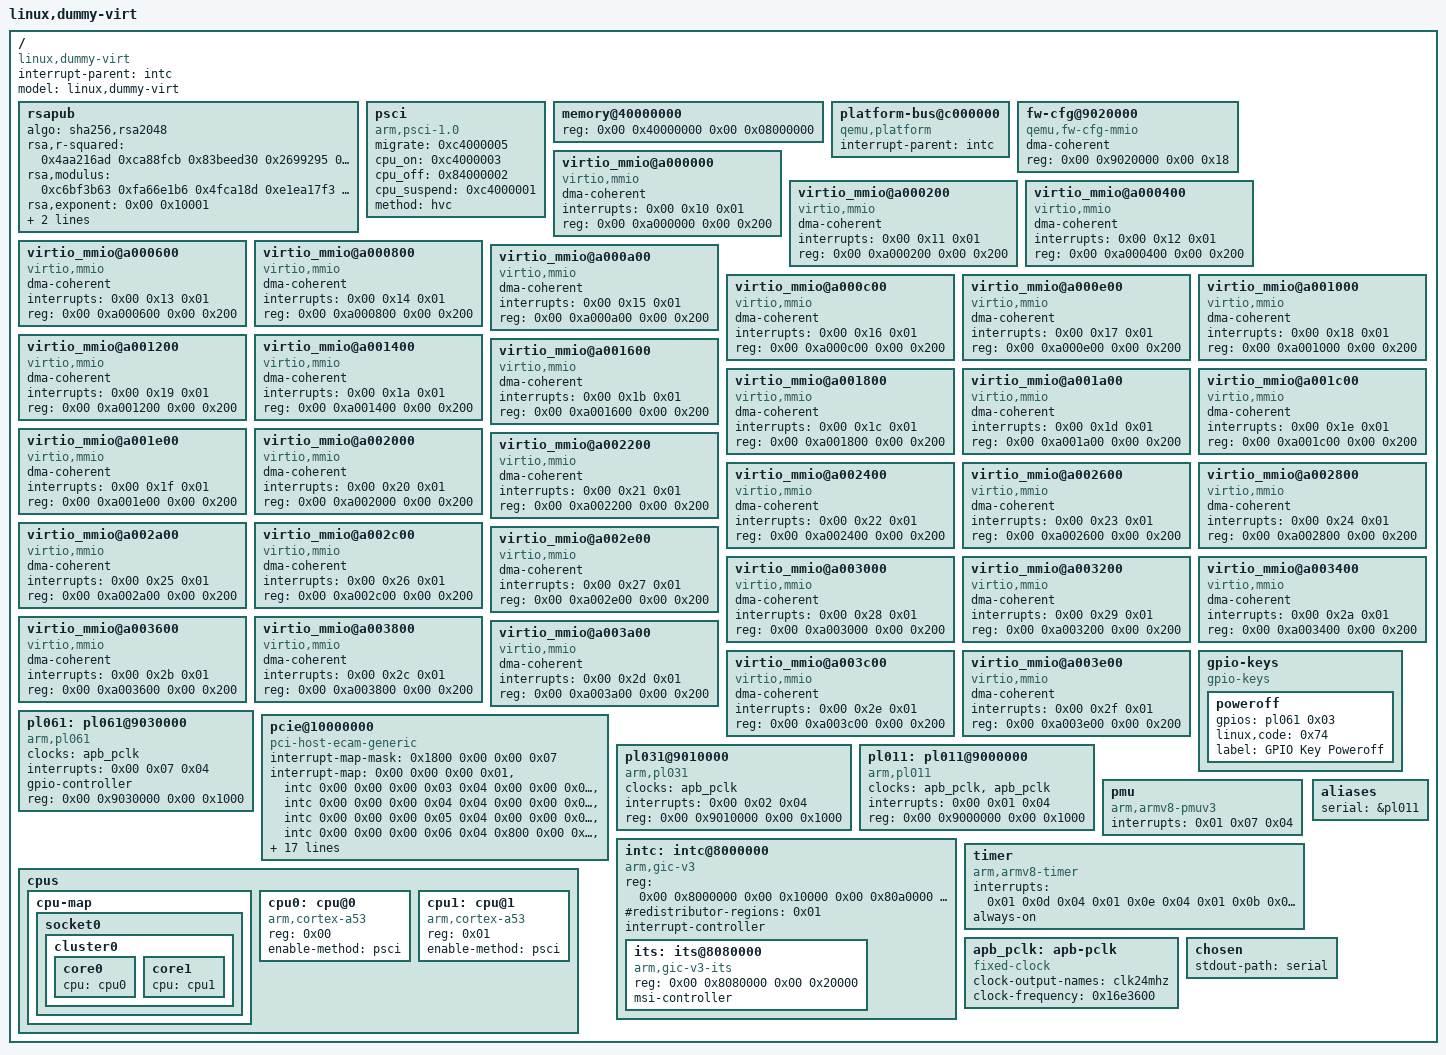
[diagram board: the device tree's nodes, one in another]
/dts-v1/;

/ {
	interrupt-parent = <&intc>;
	model = "linux,dummy-virt";
	#size-cells = <0x02>;
	#address-cells = <0x02>;
	compatible = "linux,dummy-virt";

	rsapub {
		algo = "sha256,rsa2048";
		rsa,r-squared = <0x4aa216ad 0xca88fcb 0x83beed30 0x2699295 0xf1afaef1 0x663e275e 0x19fa1227 0xb83d5ba3 0x43e199b8 0xd6899b14 0x4080062c 0xe27ea068 0xb2cbdb31 0x39768148 0x6f4cea3e 0x546d6990 0x51e88129 0xdb19710 0xa0184961 0x5ab6231d 0xc429c3dc 0xe7d1cb2b 0x63da5958 0x840e2b14 0x6644892a 0xb4f9f666 0x2552653a 0x16837f33 0x7ed7004a 0xba52a9f3 0x25413042 0xb91ebefd 0x2e3ef636 0x78a22c37 0x52dc3454 0x63b33b5 0xacee4539 0x49e8f7b6 0x8022eb2e 0xa7a001ea 0x9b777c26 0x40e1b15c 0x6eeed8e8 0xad6357a0 0x7f3c8cda 0x26c5c372 0xe377980c 0x3e431736 0xcdea5f7d 0x110a697d 0x111d53b0 0x27730100 0x738f9021 0x1fd3392a 0xaff45290 0x63d99fe7 0x4a09e67a 0xdbefd05d 0xab39db9a 0xe329a097 0x8de7c060 0x11e8d8ea 0x37a7bced 0xe69151c6>;
		rsa,modulus = <0xc6bf3b63 0xfa66e1b6 0x4fca18d 0xe1ea17f3 0xae2a3788 0x447abb5a 0x84d89a56 0xa434a3ac 0x7704144d 0xb8bd8b6e 0x27553191 0x89627597 0xbd01c377 0x52e8e12c 0x68712319 0x9aa26344 0xa7e7bca8 0xd727d465 0xe27ec55e 0x5ce4371 0x2d53f51d 0x3a14ba49 0x6ecacc06 0xd6561ff7 0xe3d4cb69 0x1238e84c 0x3b7a91b4 0xa4dfc5b4 0x273e10df 0x132defd2 0xf65991a9 0xd9da33a1 0x2e41eb73 0xe48ef4b5 0x619e852 0xc041f985 0x7777707e 0xe8074f31 0x20276d03 0xce9bbc47 0x321b9398 0x2a8e88f1 0xff1bad1c 0x8f127e80 0xa64ff0e8 0xabfa8a48 0x440102f1 0x85509ce7 0xd56d3b1f 0x8f580f09 0xfce683f1 0xcc9c589a 0x4b31ca83 0xafb93fbc 0xf1669786 0xe7cd623 0x6797b351 0xc598703f 0x1ed05880 0xd96da721 0x5d976f69 0xa6ccb449 0x5e6be39 0xb6ffdc83>;
		rsa,exponent = <0x00 0x10001>;
		rsa,n0-inverse = <0xcd33add5>;
		rsa,num-bits = <0x800>;
	};

	psci {
		migrate = <0xc4000005>;
		cpu_on = <0xc4000003>;
		cpu_off = <0x84000002>;
		cpu_suspend = <0xc4000001>;
		method = "hvc";
		compatible = "arm,psci-1.0", "arm,psci-0.2", "arm,psci";
	};

	memory@40000000 {
		reg = <0x00 0x40000000 0x00 0x08000000>;
		device_type = "memory";
	};

	platform-bus@c000000 {
		interrupt-parent = <&intc>;
		ranges = <0x00 0x00 0xc000000 0x2000000>;
		#address-cells = <0x01>;
		#size-cells = <0x01>;
		compatible = "qemu,platform", "simple-bus";
	};

	fw-cfg@9020000 {
		dma-coherent;
		reg = <0x00 0x9020000 0x00 0x18>;
		compatible = "qemu,fw-cfg-mmio";
	};

	virtio_mmio@a000000 {
		dma-coherent;
		interrupts = <0x00 0x10 0x01>;
		reg = <0x00 0xa000000 0x00 0x200>;
		compatible = "virtio,mmio";
	};

	virtio_mmio@a000200 {
		dma-coherent;
		interrupts = <0x00 0x11 0x01>;
		reg = <0x00 0xa000200 0x00 0x200>;
		compatible = "virtio,mmio";
	};

	virtio_mmio@a000400 {
		dma-coherent;
		interrupts = <0x00 0x12 0x01>;
		reg = <0x00 0xa000400 0x00 0x200>;
		compatible = "virtio,mmio";
	};

	virtio_mmio@a000600 {
		dma-coherent;
		interrupts = <0x00 0x13 0x01>;
		reg = <0x00 0xa000600 0x00 0x200>;
		compatible = "virtio,mmio";
	};

	virtio_mmio@a000800 {
		dma-coherent;
		interrupts = <0x00 0x14 0x01>;
		reg = <0x00 0xa000800 0x00 0x200>;
		compatible = "virtio,mmio";
	};

	virtio_mmio@a000a00 {
		dma-coherent;
		interrupts = <0x00 0x15 0x01>;
		reg = <0x00 0xa000a00 0x00 0x200>;
		compatible = "virtio,mmio";
	};

	virtio_mmio@a000c00 {
		dma-coherent;
		interrupts = <0x00 0x16 0x01>;
		reg = <0x00 0xa000c00 0x00 0x200>;
		compatible = "virtio,mmio";
	};

	virtio_mmio@a000e00 {
		dma-coherent;
		interrupts = <0x00 0x17 0x01>;
		reg = <0x00 0xa000e00 0x00 0x200>;
		compatible = "virtio,mmio";
	};

	virtio_mmio@a001000 {
		dma-coherent;
		interrupts = <0x00 0x18 0x01>;
		reg = <0x00 0xa001000 0x00 0x200>;
		compatible = "virtio,mmio";
	};

	virtio_mmio@a001200 {
		dma-coherent;
		interrupts = <0x00 0x19 0x01>;
		reg = <0x00 0xa001200 0x00 0x200>;
		compatible = "virtio,mmio";
	};

	virtio_mmio@a001400 {
		dma-coherent;
		interrupts = <0x00 0x1a 0x01>;
		reg = <0x00 0xa001400 0x00 0x200>;
		compatible = "virtio,mmio";
	};

	virtio_mmio@a001600 {
		dma-coherent;
		interrupts = <0x00 0x1b 0x01>;
		reg = <0x00 0xa001600 0x00 0x200>;
		compatible = "virtio,mmio";
	};

	virtio_mmio@a001800 {
		dma-coherent;
		interrupts = <0x00 0x1c 0x01>;
		reg = <0x00 0xa001800 0x00 0x200>;
		compatible = "virtio,mmio";
	};

	virtio_mmio@a001a00 {
		dma-coherent;
		interrupts = <0x00 0x1d 0x01>;
		reg = <0x00 0xa001a00 0x00 0x200>;
		compatible = "virtio,mmio";
	};

	virtio_mmio@a001c00 {
		dma-coherent;
		interrupts = <0x00 0x1e 0x01>;
		reg = <0x00 0xa001c00 0x00 0x200>;
		compatible = "virtio,mmio";
	};

	virtio_mmio@a001e00 {
		dma-coherent;
		interrupts = <0x00 0x1f 0x01>;
		reg = <0x00 0xa001e00 0x00 0x200>;
		compatible = "virtio,mmio";
	};

	virtio_mmio@a002000 {
		dma-coherent;
		interrupts = <0x00 0x20 0x01>;
		reg = <0x00 0xa002000 0x00 0x200>;
		compatible = "virtio,mmio";
	};

	virtio_mmio@a002200 {
		dma-coherent;
		interrupts = <0x00 0x21 0x01>;
		reg = <0x00 0xa002200 0x00 0x200>;
		compatible = "virtio,mmio";
	};

	virtio_mmio@a002400 {
		dma-coherent;
		interrupts = <0x00 0x22 0x01>;
		reg = <0x00 0xa002400 0x00 0x200>;
		compatible = "virtio,mmio";
	};

	virtio_mmio@a002600 {
		dma-coherent;
		interrupts = <0x00 0x23 0x01>;
		reg = <0x00 0xa002600 0x00 0x200>;
		compatible = "virtio,mmio";
	};

	virtio_mmio@a002800 {
		dma-coherent;
		interrupts = <0x00 0x24 0x01>;
		reg = <0x00 0xa002800 0x00 0x200>;
		compatible = "virtio,mmio";
	};

	virtio_mmio@a002a00 {
		dma-coherent;
		interrupts = <0x00 0x25 0x01>;
		reg = <0x00 0xa002a00 0x00 0x200>;
		compatible = "virtio,mmio";
	};

	virtio_mmio@a002c00 {
		dma-coherent;
		interrupts = <0x00 0x26 0x01>;
		reg = <0x00 0xa002c00 0x00 0x200>;
		compatible = "virtio,mmio";
	};

	virtio_mmio@a002e00 {
		dma-coherent;
		interrupts = <0x00 0x27 0x01>;
		reg = <0x00 0xa002e00 0x00 0x200>;
		compatible = "virtio,mmio";
	};

	virtio_mmio@a003000 {
		dma-coherent;
		interrupts = <0x00 0x28 0x01>;
		reg = <0x00 0xa003000 0x00 0x200>;
		compatible = "virtio,mmio";
	};

	virtio_mmio@a003200 {
		dma-coherent;
		interrupts = <0x00 0x29 0x01>;
		reg = <0x00 0xa003200 0x00 0x200>;
		compatible = "virtio,mmio";
	};

	virtio_mmio@a003400 {
		dma-coherent;
		interrupts = <0x00 0x2a 0x01>;
		reg = <0x00 0xa003400 0x00 0x200>;
		compatible = "virtio,mmio";
	};

	virtio_mmio@a003600 {
		dma-coherent;
		interrupts = <0x00 0x2b 0x01>;
		reg = <0x00 0xa003600 0x00 0x200>;
		compatible = "virtio,mmio";
	};

	virtio_mmio@a003800 {
		dma-coherent;
		interrupts = <0x00 0x2c 0x01>;
		reg = <0x00 0xa003800 0x00 0x200>;
		compatible = "virtio,mmio";
	};

	virtio_mmio@a003a00 {
		dma-coherent;
		interrupts = <0x00 0x2d 0x01>;
		reg = <0x00 0xa003a00 0x00 0x200>;
		compatible = "virtio,mmio";
	};

	virtio_mmio@a003c00 {
		dma-coherent;
		interrupts = <0x00 0x2e 0x01>;
		reg = <0x00 0xa003c00 0x00 0x200>;
		compatible = "virtio,mmio";
	};

	virtio_mmio@a003e00 {
		dma-coherent;
		interrupts = <0x00 0x2f 0x01>;
		reg = <0x00 0xa003e00 0x00 0x200>;
		compatible = "virtio,mmio";
	};

	gpio-keys {
		compatible = "gpio-keys";

		poweroff {
			gpios = <&pl061 0x03 0x00>;
			linux,code = <0x74>;
			label = "GPIO Key Poweroff";
		};
	};

	pl061: pl061@9030000 {
		clock-names = "apb_pclk";
		clocks = <&apb_pclk>;
		interrupts = <0x00 0x07 0x04>;
		gpio-controller;
		#gpio-cells = <0x02>;
		compatible = "arm,pl061", "arm,primecell";
		reg = <0x00 0x9030000 0x00 0x1000>;
	};

	pcie@10000000 {
		interrupt-map-mask = <0x1800 0x00 0x00 0x07>;
		interrupt-map = <0x00 0x00 0x00 0x01 &intc 0x00 0x00 0x00 0x03 0x04
			0x00 0x00 0x00 0x02 &intc 0x00 0x00 0x00 0x04 0x04
			0x00 0x00 0x00 0x03 &intc 0x00 0x00 0x00 0x05 0x04
			0x00 0x00 0x00 0x04 &intc 0x00 0x00 0x00 0x06 0x04
			0x800 0x00 0x00 0x01 &intc 0x00 0x00 0x00 0x04 0x04
			0x800 0x00 0x00 0x02 &intc 0x00 0x00 0x00 0x05 0x04
			0x800 0x00 0x00 0x03 &intc 0x00 0x00 0x00 0x06 0x04
			0x800 0x00 0x00 0x04 &intc 0x00 0x00 0x00 0x03 0x04
			0x1000 0x00 0x00 0x01 &intc 0x00 0x00 0x00 0x05 0x04
			0x1000 0x00 0x00 0x02 &intc 0x00 0x00 0x00 0x06 0x04
			0x1000 0x00 0x00 0x03 &intc 0x00 0x00 0x00 0x03 0x04
			0x1000 0x00 0x00 0x04 &intc 0x00 0x00 0x00 0x04 0x04
			0x1800 0x00 0x00 0x01 &intc 0x00 0x00 0x00 0x06 0x04
			0x1800 0x00 0x00 0x02 &intc 0x00 0x00 0x00 0x03 0x04
			0x1800 0x00 0x00 0x03 &intc 0x00 0x00 0x00 0x04 0x04
			0x1800 0x00 0x00 0x04 &intc 0x00 0x00 0x00 0x05 0x04>;
		#interrupt-cells = <0x01>;
		ranges = <0x1000000 0x00 0x00 0x00 0x3eff0000 0x00 0x10000 0x2000000 0x00 0x10000000 0x00 0x10000000 0x00 0x2eff0000 0x3000000 0x80 0x00 0x80 0x00 0x80 0x00>;
		reg = <0x40 0x10000000 0x00 0x10000000>;
		msi-map = <0x00 &its 0x00 0x10000>;
		dma-coherent;
		bus-range = <0x00 0xff>;
		linux,pci-domain = <0x00>;
		#size-cells = <0x02>;
		#address-cells = <0x03>;
		device_type = "pci";
		compatible = "pci-host-ecam-generic";
	};

	pl031@9010000 {
		clock-names = "apb_pclk";
		clocks = <&apb_pclk>;
		interrupts = <0x00 0x02 0x04>;
		reg = <0x00 0x9010000 0x00 0x1000>;
		compatible = "arm,pl031", "arm,primecell";
	};

	pl011: pl011@9000000 {
		clock-names = "uartclk", "apb_pclk";
		clocks = <&apb_pclk &apb_pclk>;
		interrupts = <0x00 0x01 0x04>;
		reg = <0x00 0x9000000 0x00 0x1000>;
		compatible = "arm,pl011", "arm,primecell";
	};

	pmu {
		interrupts = <0x01 0x07 0x04>;
		compatible = "arm,armv8-pmuv3";
	};

	intc: intc@8000000 {
		reg = <0x00 0x8000000 0x00 0x10000 0x00 0x80a0000 0x00 0xf60000>;
		#redistributor-regions = <0x01>;
		compatible = "arm,gic-v3";
		ranges;
		#size-cells = <0x02>;
		#address-cells = <0x02>;
		interrupt-controller;
		#interrupt-cells = <0x03>;

		its: its@8080000 {
			reg = <0x00 0x8080000 0x00 0x20000>;
			#msi-cells = <0x01>;
			msi-controller;
			compatible = "arm,gic-v3-its";
		};
	};

	cpus {
		#size-cells = <0x00>;
		#address-cells = <0x01>;

		cpu-map {

			socket0 {

				cluster0 {

					core0 {
						cpu = <&cpu0>;
					};

					core1 {
						cpu = <&cpu1>;
					};
				};
			};
		};

		cpu0: cpu@0 {
			reg = <0x00>;
			enable-method = "psci";
			compatible = "arm,cortex-a53";
			device_type = "cpu";
		};

		cpu1: cpu@1 {
			reg = <0x01>;
			enable-method = "psci";
			compatible = "arm,cortex-a53";
			device_type = "cpu";
		};
	};

	timer {
		interrupts = <0x01 0x0d 0x04 0x01 0x0e 0x04 0x01 0x0b 0x04 0x01 0x0a 0x04>;
		always-on;
		compatible = "arm,armv8-timer", "arm,armv7-timer";
	};

	apb_pclk: apb-pclk {
		clock-output-names = "clk24mhz";
		clock-frequency = <0x16e3600>;
		#clock-cells = <0x00>;
		compatible = "fixed-clock";
	};

	aliases {
		serial = &pl011;
	};

	chosen {
		stdout-path = "serial";
	};
};
